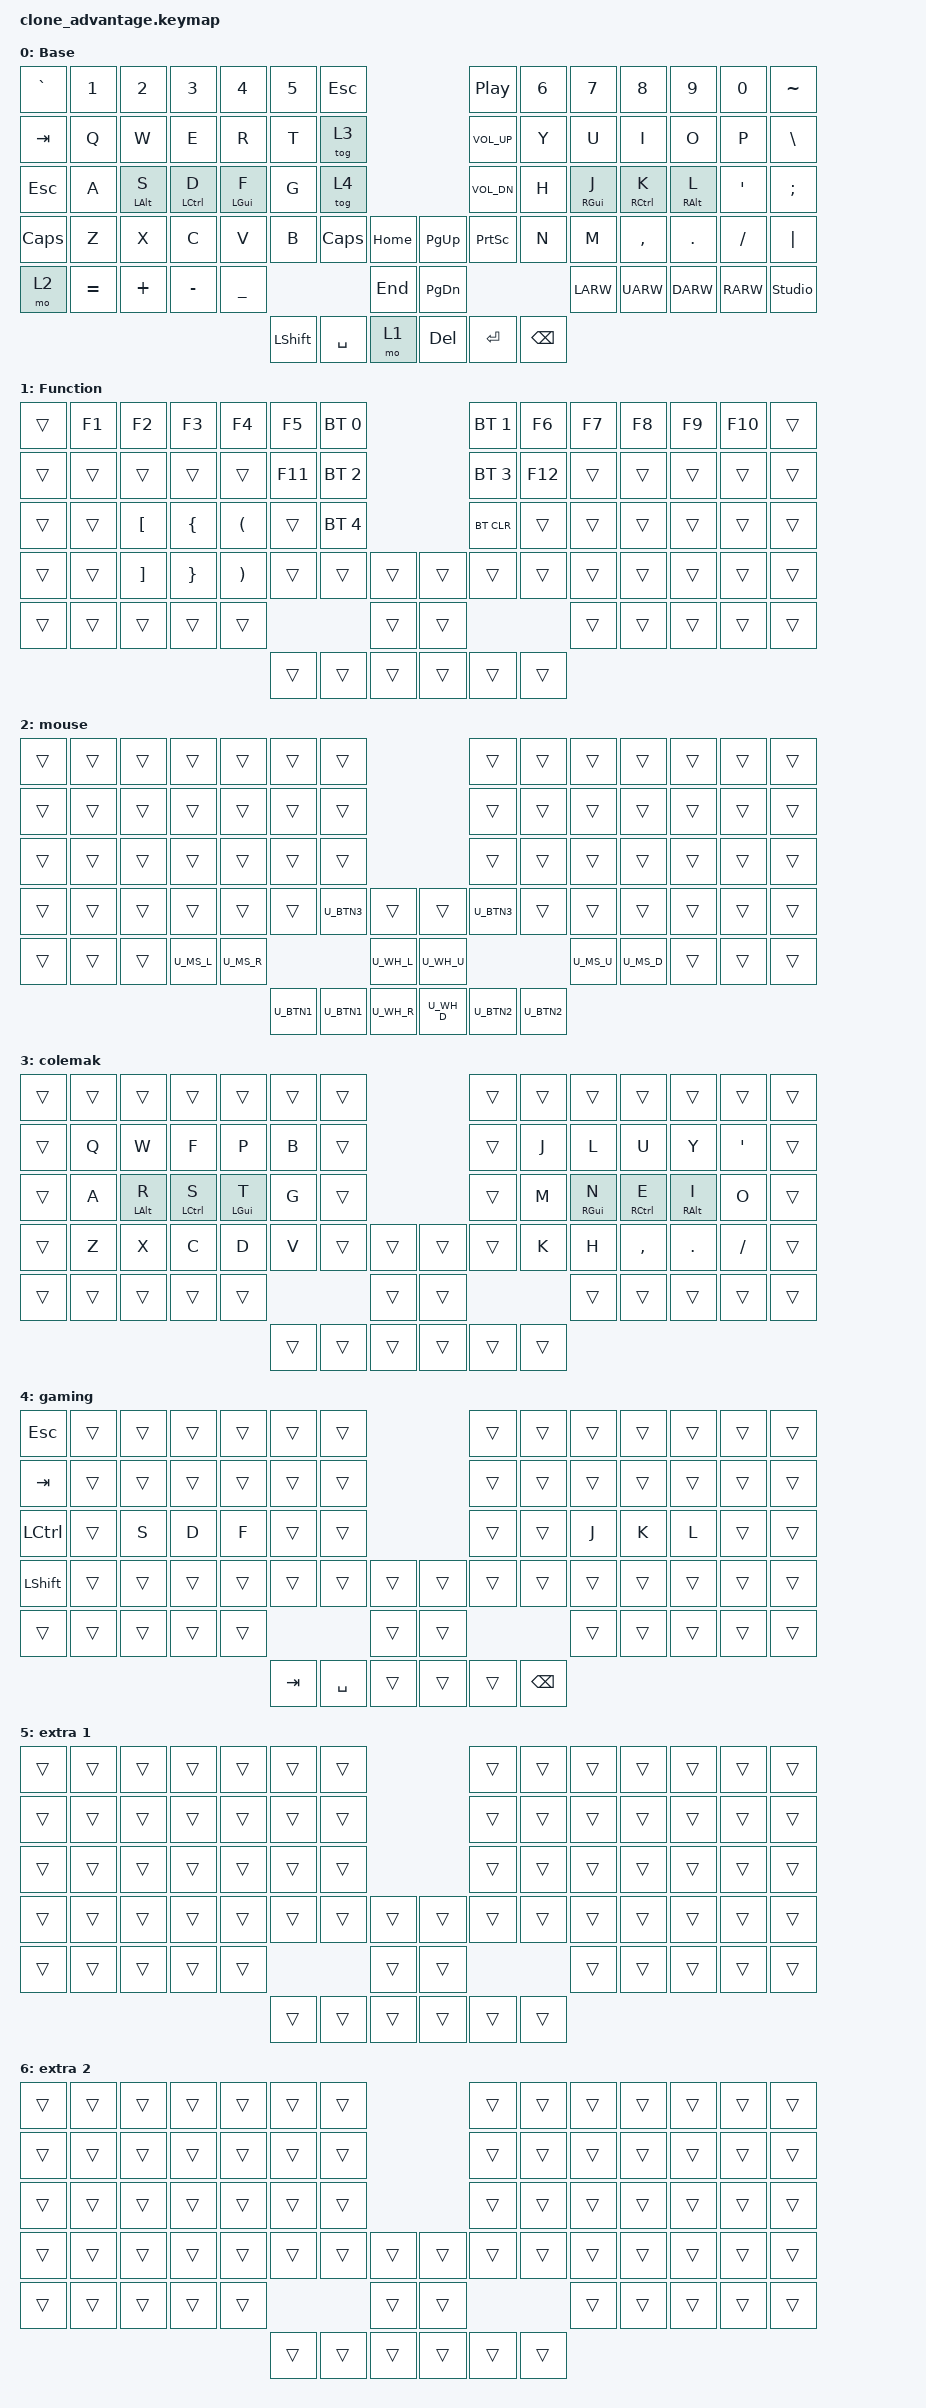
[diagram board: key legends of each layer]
#include <behaviors.dtsi>
#include <dt-bindings/zmk/keys.h>
#include <dt-bindings/zmk/bt.h>
#include <dt-bindings/zmk/outputs.h>
#include <dt-bindings/zmk/rgb.h>
#include <dt-bindings/zmk/backlight.h>

/* definitions for mouse layer */
#include "mouse.dtsi"

#define ___ &trans

#define QWERTY 0
#define COLEMAK 1
#define KEYPAD 2
#define FN 3
#define MOD 4
#define MS 5

&lt {
        #binding-cells = <2>;
        tapping-term-ms = <200>;
        quick-tap-ms = <0>;
        flavor = "tap-preferred";
};

/ {
    behaviors {
        hm: homerow_mods {
            compatible = "zmk,behavior-hold-tap";
            label = "HOMEROW_MODS";
            #binding-cells = <2>;
            tapping-term-ms = <200>;
            quick-tap-ms = <0>;
            flavor = "tap-preferred";
            bindings = <&kp>, <&kp>;
        };
    };
    keymap {
        compatible = "zmk,keymap";

        base_layer {
            display-name = "Base";
            bindings = <
             //╭──────────┬──────────┬───────── ─┬────────────┬───────────┬───────────┬──────────╮                         ╭──────────────┬─────────┬────────────┬────────────┬──────────┬─────────┬──────────╮     
                 &kp GRAVE  &kp N1     &kp N2      &kp N3       &kp N4      &kp N5      &kp ESC                              &kp C_PP       &kp N6    &kp N7       &kp N8       &kp N9     &kp N0    &kp TILDE
             //├──────────┼──────────┼───────── ─┼────────────┼───────────┼───────────┼──────────┤                         ├──────────────┼─────────┼────────────┼────────────┼──────────┼─────────┼──────────┤
                 &kp TAB    &kp Q      &kp W       &kp E        &kp R       &kp T       &tog 3                               &kp C_VOL_UP   &kp Y     &kp U        &kp I        &kp O      &kp P     &kp BSLH
             //├──────────┼──────────┼──────── ──┼────────────┼───────────┼───────────┼──────────┤                         ├──────────────┼─────────┼────────────┼────────────┼──────────┼─────────┼──────────┤
                 &kp ESC    &kp A      &hm LALT S  &hm LCTRL D  &hm LGUI F  &kp G       &tog 4                               &kp C_VOL_DN   &kp H     &hm RGUI J   &hm RCTRL K  &hm RALT L &kp SQT   &kp SEMI
             //├──────────┼──────────┼─────── ───┼────────────┼───────────┼───────────┼──────────┤──────────╮   ╭──────────├──────────────┼─────────┼   ────────────┼────────────┼──────────┼─────────┼──────────┤
                 &kp CAPS   &kp Z      &kp X       &kp C        &kp V       &kp B       &kp CAPS   &kp HOME       &kp PG_UP  &kp PSCRN      &kp N     &kp M        &kp COMMA    &kp DOT    &kp FSLH  &kp PIPE
             //├──────────┼──────────┼──────── ──┼────────────┼───────────┼───────────┼──────────┤──────────┤   ├──────────├──────────────┼─────────┼────────────┼────────────┼──────────┼─────────┼──────────┤
                 &mo 2      &kp EQUAL  &kp PLUS    &kp MINUS    &kp UNDER                          &kp END        &kp PG_DN                           &kp LARW     &kp UARW     &kp DARW   &kp RARW  &studio_unlock
             //╰──────────┴──────────┴──────── ──┴────────────┴───────────┼───────────┼──────────┤──────────┤   ├──────────├──────────────┼─────────┼────────────┴────────────┴──────────┴─────────┴──────────╯
                                                                           &kp LSHFT   &kp SPACE   &mo 1          &kp DEL    &kp ENTER      &kp BSPC
             //                                                           ╰───────────┴──────────┴──────────╯   ╰──────────┴──────────────┴─────────╯        
            >;
        };

        fn_layer {
            display-name = "Function";
            bindings = <
             //╭──────────┬──────────┬──────────┬──────────┬──────────┬──────────┬──────────╮                         ╭──────────┬──────────┬──────────┬──────────┬──────────┬──────────┬──────────╮                
                 ___        &kp F1     &kp F2     &kp F3     &kp F4     &kp F5     &bt BT_SEL 0                     &bt BT_SEL 1   &kp F6     &kp F7     &kp F8     &kp F9     &kp F10     ___                     
             //├──────────┼──────────┼──────────┼──────────┼──────────┼──────────┼──────────┤                         ├──────────┼──────────┼──────────┼──────────┼──────────┼──────────┼──────────┤           
                 ___        ___        ___        ___        ___        &kp F11    &bt BT_SEL 2                     &bt BT_SEL 3   &kp F12    ___        ___        ___        ___        ___                     
             //├──────────┼──────────┼──────────┼──────────┼──────────┼──────────┼──────────┤                         ├──────────┼──────────┼──────────┼──────────┼──────────┼──────────┼──────────┤           
                 ___        ___        &kp LBKT   &kp LBRC   &kp LPAR   ___        &bt BT_SEL 4                     &bt BT_CLR     ___        ___        ___        ___       ___        ___                     
             //├──────────┼──────────┼──────────┼──────────┼──────────┼──────────┼──────────┤──────────╮   ╭──────────┼──────────┼──────────┼──────────┼──────────┼──────────┼──────────┤──────────┤
                 ___        ___        &kp RBKT   &kp RBRC   &kp RPAR   ___         ___        ___            ___        ___       ___        ___        ___        ___        ___        ___       
             //├──────────┼──────────┼──────────┼──────────┼──────────┼──────────┼──────────┤──────────┤   ├──────────┼──────────┼──────────┼──────────┼──────────┼──────────┼──────────┤──────────┤
                 ___        ___        ___        ___        ___                               ___            ___                              ___        ___        ___        ___        ___       
             //╰──────────┴──────────┴──────────┴──────────┴──────────┴──────────┼──────────┼──────────┤   ├──────────┴──────────┴──────────┴──────────┴──────────┴──────────┼──────────┼──────────╯        
                                                                        ___         ___        ___            ___         ___       ___     
             //                                                       ╰──────────┴──────────┴──────────╯   ╰──────────┴──────────┴──────────╯        
            >;
        };

        mouse_layer {
            display-name = "mouse";
            bindings = <
             //╭──────────┬──────────┬──────────┬──────────┬──────────┬──────────┬──────────╮                         ╭──────────┬──────────┬──────────┬──────────┬──────────┬──────────┬──────────╮                
                 ___        ___        ___        ___        ___        ___         ___                                  ___       ___        ___        ___        ___        ___         ___                     
             //├──────────┼──────────┼──────────┼──────────┼──────────┼──────────┼──────────┤                         ├──────────┼──────────┼──────────┼──────────┼──────────┼──────────┼──────────┤           
                 ___        ___        ___        ___        ___        ___         ___                                   ___      ___        ___        ___        ___        ___        ___                     
             //├──────────┼──────────┼──────────┼──────────┼──────────┼──────────┼──────────┤                         ├──────────┼──────────┼──────────┼──────────┼──────────┼──────────┼──────────┤           
                 ___        ___        ___        ___        ___        ___        ___                                  ___        ___        ___        ___        ___         ___        ___                     
             //├──────────┼──────────┼──────────┼──────────┼──────────┼──────────┼──────────┤──────────╮   ╭──────────┼──────────┼──────────┼──────────┼──────────┼──────────┼──────────┤──────────┤
                 ___        ___        ___        ___        ___        ___        U_BTN3      ___            ___        U_BTN3    ___        ___        ___        ___        ___        ___       
             //├──────────┼──────────┼──────────┼──────────┼──────────┼──────────┼──────────┤──────────┤   ├──────────┼──────────┼──────────┼──────────┼──────────┼──────────┼──────────┤──────────┤
                 ___        ___        ___        U_MS_L     U_MS_R                           U_WH_L          U_WH_U                          U_MS_U     U_MS_D     ___        ___        ___       
             //╰──────────┴──────────┴──────────┴──────────┴──────────┴──────────┼──────────┼──────────┤   ├──────────┴──────────┴──────────┴──────────┴──────────┴──────────┼──────────┼──────────╯        
                                                                         U_BTN1    U_BTN1     U_WH_R          U_WH_D     U_BTN2    U_BTN2     
             //                                                       ╰──────────┴──────────┴──────────╯   ╰──────────┴──────────┴──────────╯        
            >;
        };

        colemakdh_layer {
            display-name = "colemak";
            bindings = <
             //╭──────────┬──────────┬──────────┬──────────┬──────────┬──────────┬──────────╮                         ╭──────────┬──────────┬──────────┬──────────┬──────────┬──────────┬──────────╮                
                 ___        ___        ___        ___        ___        ___         ___                                 ___       ___        ___        ___        ___        ___        ___                     
             //├──────────┼──────────┼──────────┼──────────┼──────────┼──────────┼──────────┤                         ├──────────┼──────────┼──────────┼──────────┼──────────┼──────────┼──────────┤           
                 ___        &kp Q      &kp W      &kp F      &kp P      &kp B       ___                                 ___        &kp J      &kp L      &kp U      &kp Y      &kp SQT    ___                     
             //├──────────┼──────────┼──────────┼──────────┼──────────┼──────────┼──────────┤                         ├──────────┼──────────┼──────────┼──────────┼──────────┼──────────┼──────────┤           
                 ___        &kp A      &hm LALT R &hm LCTRL S  &hm LGUI T  &kp G    ___                                 ___        &kp M     &hm RGUI N  &hm RCTRL E &hm RALT I  &kp O   ___                     
             //├──────────┼──────────┼──────────┼──────────┼──────────┼──────────┼──────────┤──────────╮   ╭──────────┼──────────┼──────────┼──────────┼──────────┼──────────┼──────────┤──────────┤
                 ___        &kp Z      &kp X      &kp C      &kp D       &kp V       ___        ___           ___        ___        &kp K      &kp H      &kp COMMA  &kp DOT    &kp FSLH      ___       
             //├──────────┼──────────┼──────────┼──────────┼──────────┼──────────┼──────────┤──────────┤   ├──────────┼──────────┼──────────┼──────────┼──────────┼──────────┼──────────┤──────────┤
                 ___        ___        ___        ___        ___                              ___            ___                             ___        ___        ___        ___        ___       
             //╰──────────┴──────────┴──────────┴──────────┴──────────┴──────────┼──────────┼──────────┤   ├──────────┴──────────┴──────────┴──────────┴──────────┴──────────┼──────────┼──────────╯        
                                                                         ___        ___        ___           ___        ___        ___          
             //                                                       ╰──────────┴──────────┴──────────╯   ╰──────────┴──────────┴──────────╯        
            >;
        };

        gaming_layer {
            display-name = "gaming";
            bindings = <
             //╭──────────┬──────────┬──────────┬──────────┬──────────┬──────────┬──────────╮                         ╭──────────┬──────────┬──────────┬──────────┬──────────┬──────────┬──────────╮                
                 &kp ESC    ___        ___        ___        ___        ___         ___                                 ___       ___        ___        ___        ___        ___        ___                     
             //├──────────┼──────────┼──────────┼──────────┼──────────┼──────────┼──────────┤                         ├──────────┼──────────┼──────────┼──────────┼──────────┼──────────┼──────────┤           
                 &kp TAB    ___        ___        ___        ___        ___         ___                                 ___       ___        ___        ___        ___        ___        ___                     
             //├──────────┼──────────┼──────────┼──────────┼──────────┼──────────┼──────────┤                         ├──────────┼──────────┼──────────┼──────────┼──────────┼──────────┼──────────┤           
                 &kp LCTRL  ___        &kp S      &kp D      &kp F      ___         ___                                 ___        ___        &kp J      &kp K      &kp L     ___        ___                     
             //├──────────┼──────────┼──────────┼──────────┼──────────┼──────────┼──────────┤──────────╮   ╭──────────┼──────────┼──────────┼──────────┼──────────┼──────────┼──────────┤──────────┤
                 &kp LSHFT  ___        ___        ___        ___        ___          ___       ___           ___        ___       ___        ___        ___        ___        ___            ___       
             //├──────────┼──────────┼──────────┼──────────┼──────────┼──────────┼──────────┤──────────┤   ├──────────┼──────────┼──────────┼──────────┼──────────┼──────────┼──────────┤──────────┤
                 ___        ___        ___        ___        ___                               ___            ___                             ___        ___        ___        ___        ___       
             //╰──────────┴──────────┴──────────┴──────────┴──────────┴──────────┼──────────┼──────────┤   ├──────────┴──────────┴──────────┴──────────┴──────────┴──────────┼──────────┼──────────╯        
                                                                        &kp TAB    &kp SPACE   ___           ___        ___       &kp BSPC          
             //                                                       ╰──────────┴──────────┴──────────╯   ╰──────────┴──────────┴──────────╯        
            >;
        };

        extra1_layer {
            display-name = "extra 1";
            bindings = <
             //╭──────────┬──────────┬──────────┬──────────┬──────────┬──────────┬──────────╮                         ╭──────────┬──────────┬──────────┬──────────┬──────────┬──────────┬──────────╮                
                 ___        ___        ___        ___        ___        ___         ___                                  ___       ___        ___        ___        ___        ___         ___                     
             //├──────────┼──────────┼──────────┼──────────┼──────────┼──────────┼──────────┤                         ├──────────┼──────────┼──────────┼──────────┼──────────┼──────────┼──────────┤           
                 ___        ___        ___        ___        ___        ___         ___                                   ___      ___        ___        ___        ___        ___        ___                     
             //├──────────┼──────────┼──────────┼──────────┼──────────┼──────────┼──────────┤                         ├──────────┼──────────┼──────────┼──────────┼──────────┼──────────┼──────────┤           
                 ___        ___        ___        ___        ___        ___        ___                                  ___        ___        ___        ___        ___         ___        ___                     
             //├──────────┼──────────┼──────────┼──────────┼──────────┼──────────┼──────────┤──────────╮   ╭──────────┼──────────┼──────────┼──────────┼──────────┼──────────┼──────────┤──────────┤
                 ___        ___        ___        ___        ___        ___        ___        ___            ___        ___        ___        ___        ___        ___        ___        ___       
             //├──────────┼──────────┼──────────┼──────────┼──────────┼──────────┼──────────┤──────────┤   ├──────────┼──────────┼──────────┼──────────┼──────────┼──────────┼──────────┤──────────┤
                 ___        ___        ___        ___        ___                              ___            ___                             ___        ___     ___        ___        ___       
             //╰──────────┴──────────┴──────────┴──────────┴──────────┴──────────┼──────────┼──────────┤   ├──────────┴──────────┴──────────┴──────────┴──────────┴──────────┼──────────┼──────────╯        
                                                                          ___       ___       ___             ___       ___      ___     
             //                                                       ╰──────────┴──────────┴──────────╯   ╰──────────┴──────────┴──────────╯        
            >;
        };

         extra2_layer {
            display-name = "extra 2";
            bindings = <
             //╭──────────┬──────────┬──────────┬──────────┬──────────┬──────────┬──────────╮                         ╭──────────┬──────────┬──────────┬──────────┬──────────┬──────────┬──────────╮                
                 ___        ___        ___        ___        ___        ___         ___                                  ___       ___        ___        ___        ___        ___         ___                     
             //├──────────┼──────────┼──────────┼──────────┼──────────┼──────────┼──────────┤                         ├──────────┼──────────┼──────────┼──────────┼──────────┼──────────┼──────────┤           
                 ___        ___        ___        ___        ___        ___         ___                                   ___      ___        ___        ___        ___        ___        ___                     
             //├──────────┼──────────┼──────────┼──────────┼──────────┼──────────┼──────────┤                         ├──────────┼──────────┼──────────┼──────────┼──────────┼──────────┼──────────┤           
                 ___        ___        ___        ___        ___        ___        ___                                  ___        ___        ___        ___        ___         ___        ___                     
             //├──────────┼──────────┼──────────┼──────────┼──────────┼──────────┼──────────┤──────────╮   ╭──────────┼──────────┼──────────┼──────────┼──────────┼──────────┼──────────┤──────────┤
                 ___        ___        ___        ___        ___        ___        ___        ___            ___        ___        ___        ___        ___        ___        ___        ___       
             //├──────────┼──────────┼──────────┼──────────┼──────────┼──────────┼──────────┤──────────┤   ├──────────┼──────────┼──────────┼──────────┼──────────┼──────────┼──────────┤──────────┤
                 ___        ___        ___        ___        ___                              ___            ___                             ___        ___     ___        ___        ___       
             //╰──────────┴──────────┴──────────┴──────────┴──────────┴──────────┼──────────┼──────────┤   ├──────────┴──────────┴──────────┴──────────┴──────────┴──────────┼──────────┼──────────╯        
                                                                          ___       ___       ___             ___       ___      ___     
             //                                                       ╰──────────┴──────────┴──────────╯   ╰──────────┴──────────┴──────────╯        
            >;
        };
    };
};
